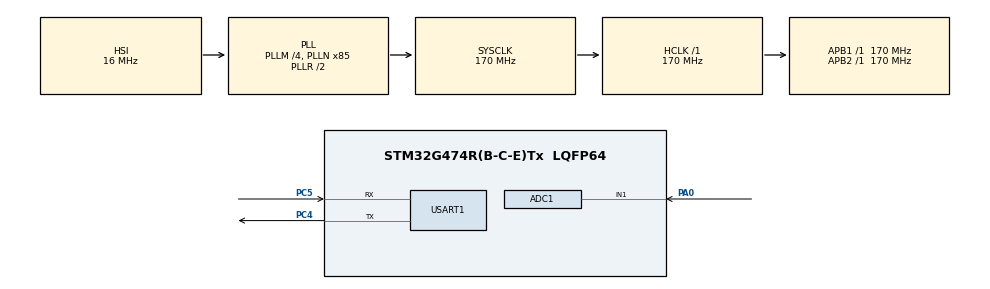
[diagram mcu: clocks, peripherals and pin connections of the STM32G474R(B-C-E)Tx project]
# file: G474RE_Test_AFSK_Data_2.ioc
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ADC1.Channel-0\#ChannelRegularConversion=ADC_CHANNEL_1
ADC1.ContinuousConvMode=ENABLE
ADC1.DMAContinuousRequests=ENABLE
ADC1.ExternalTrigConv=ADC_EXTERNALTRIG_T3_TRGO
ADC1.NbrOfConversionFlag=1
ADC1.OffsetNumber-0\#ChannelRegularConversion=ADC_OFFSET_NONE
ADC1.Rank-0\#ChannelRegularConversion=1
ADC1.SamplingTime-0\#ChannelRegularConversion=ADC_SAMPLETIME_640CYCLES_5
ADC1.master=1
Dma.ADC1.0.Direction=DMA_PERIPH_TO_MEMORY
Dma.ADC1.0.EventEnable=DISABLE
Dma.ADC1.0.Instance=DMA1_Channel1
Dma.ADC1.0.MemDataAlignment=DMA_MDATAALIGN_HALFWORD
Dma.ADC1.0.MemInc=DMA_MINC_ENABLE
Dma.ADC1.0.Mode=DMA_CIRCULAR
Dma.ADC1.0.PeriphDataAlignment=DMA_PDATAALIGN_HALFWORD
Dma.ADC1.0.PeriphInc=DMA_PINC_DISABLE
Dma.ADC1.0.Polarity=HAL_DMAMUX_REQ_GEN_RISING
Dma.ADC1.0.Priority=DMA_PRIORITY_MEDIUM
Dma.ADC1.0.RequestNumber=1
Dma.ADC1.0.SignalID=NONE
Dma.ADC1.0.SyncEnable=DISABLE
Dma.ADC1.0.SyncPolarity=HAL_DMAMUX_SYNC_NO_EVENT
Dma.ADC1.0.SyncRequestNumber=1
Dma.ADC1.0.SyncSignalID=NONE
Dma.Request0=ADC1
Mcu.Family=STM32G4
Mcu.Name=STM32G474R(B-C-E)Tx
Mcu.Package=LQFP64
NVIC.DMA1_Channel1_IRQn=true\:0\:0\:false\:false\:true\:false\:true\:true
NVIC.PriorityGroup=NVIC_PRIORITYGROUP_4
NVIC.TIM3_IRQn=true\:0\:0\:false\:false\:true\:true\:true\:true
PA0.Mode=IN1-Single-Ended
PA0.Signal=ADC1_IN1
PA13.Mode=Serial_Wire
PA13.Signal=SYS_JTMS-SWDIO
PA14.Mode=Serial_Wire
PA14.Signal=SYS_JTCK-SWCLK
PC14-OSC32_IN.Mode=LSE-External-Oscillator
PC14-OSC32_IN.Signal=RCC_OSC32_IN
PC15-OSC32_OUT.Mode=LSE-External-Oscillator
PC15-OSC32_OUT.Signal=RCC_OSC32_OUT
PC4.Mode=Asynchronous
PC4.Signal=USART1_TX
PC5.Mode=Asynchronous
PC5.Signal=USART1_RX
PF0-OSC_IN.Mode=HSE-External-Oscillator
PF0-OSC_IN.Signal=RCC_OSC_IN
PF1-OSC_OUT.Mode=HSE-External-Oscillator
PF1-OSC_OUT.Signal=RCC_OSC_OUT
ProjectManager.HeapSize=0x200
ProjectManager.StackSize=0x400
ProjectManager.TargetToolchain=STM32CubeIDE
RCC.ADC12Freq_Value=170000000
RCC.ADC345Freq_Value=170000000
RCC.AHBFreq_Value=170000000
RCC.APB1Freq_Value=170000000
RCC.APB1TimFreq_Value=170000000
RCC.APB2Freq_Value=170000000
RCC.APB2TimFreq_Value=170000000
RCC.CortexFreq_Value=170000000
RCC.EXTERNAL_CLOCK_VALUE=12288000
RCC.HCLKFreq_Value=170000000
RCC.HSE_VALUE=8000000
RCC.HSI48_VALUE=48000000
RCC.HSI_VALUE=16000000
RCC.PLLM=RCC_PLLM_DIV4
RCC.PLLN=85
RCC.SYSCLKFreq_VALUE=170000000
RCC.SYSCLKSource=RCC_SYSCLKSOURCE_PLLCLK
RCC.USBFreq_Value=170000000
RCC.VCOOutputFreq_Value=340000000
TIM3.PeriodNoDither=4249
TIM3.TIM_MasterOutputTrigger=TIM_TRGO_UPDATE
USART1.VirtualMode-Asynchronous=VM_ASYNC
VP_SYS_VS_DBSignals.Mode=DisableDeadBatterySignals
VP_TIM3_VS_ClockSourceINT.Mode=Internal
board=custom

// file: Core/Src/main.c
/* USER CODE BEGIN Header */
/**
 ******************************************************************************
 * @file           : main.c
 * @brief          : Main program body
 ******************************************************************************
 * @attention
 *
 * Copyright (c) 2025 STMicroelectronics.
 * All rights reserved.
 *
 * This software is licensed under terms that can be found in the LICENSE file
 * in the root directory of this software component.
 * If no LICENSE file comes with this software, it is provided AS-IS.
 *
 ******************************************************************************
 */
/* USER CODE END Header */
#include "main.h"

/* USER CODE BEGIN Includes */
#include <math.h>
#include <stdio.h>
#include <string.h>

/* USER CODE END Includes */

/* USER CODE BEGIN PTD */
#ifndef M_PI
#define M_PI 3.14159265358979323846f
#endif

#define SAMPLE_RATE     40000
#define BIT_RATE        100
#define SAMPLES_PER_BIT (SAMPLE_RATE/BIT_RATE)
#define FREQ_MARK       2500.0f
#define FREQ_SPACE      1500.0f
#define PREAMBLE_BYTE   0x55
#define PREAMBLE_COUNT  8
#define SYNC_BYTE       0xD5
#define MAX_PAYLOAD_LEN 64
/* USER CODE END PTD */

/* USER CODE BEGIN PD */
uint16_t adc_buf[SAMPLES_PER_BIT];
uint8_t bit_queue[16];
int q_idx = 0;
uint8_t frame[MAX_PAYLOAD_LEN];
uint8_t frame_len = 0;
uint8_t state = 0, preamble_seen = 0, len_expected = 0, crc_calc = 0;
/* USER CODE END PD */

ADC_HandleTypeDef hadc1;
DMA_HandleTypeDef hdma_adc1;

TIM_HandleTypeDef htim3;

UART_HandleTypeDef huart1;

void SystemClock_Config(void);
static void MX_GPIO_Init(void);
static void MX_DMA_Init(void);
static void MX_ADC1_Init(void);
static void MX_TIM3_Init(void);
static void MX_USART1_UART_Init(void);

/* USER CODE BEGIN 0 */
static uint8_t crc8(uint8_t crc, uint8_t data) {
	crc ^= data;
	for (int i = 0; i < 8; i++)
		crc = (crc & 0x80) ? ((crc << 1) ^ 0x07) : (crc << 1);
	return crc;
}

float goertzel(float freq, uint16_t *samples) {
	float omega = 2 * M_PI * freq / SAMPLE_RATE;
	float coeff = 2 * cosf(omega), s0 = 0, s1 = 0, s2 = 0;
	for (int i = 0; i < SAMPLES_PER_BIT; i++) {
		float x = (float) samples[i] - 2048;
		s0 = x + coeff * s1 - s2;
		s2 = s1;
		s1 = s0;
	}
	return s1 * s1 + s2 * s2 - coeff * s1 * s2;
}

void push_bit(uint8_t bit) {
	bit_queue[q_idx++] = bit;
	if (q_idx >= 10) {
		if (bit_queue[0] == 0 && bit_queue[9] == 1) {
			uint8_t val = 0;
			for (int i = 0; i < 8; i++)
				if (bit_queue[1 + i])
					val |= 1 << i;

			if (state == 0) {
				if (val == PREAMBLE_BYTE) {
					if (++preamble_seen >= PREAMBLE_COUNT)
						state = 1;
				} else
					preamble_seen = 0;
			} else if (state == 1) {
				if (val == SYNC_BYTE)
					state = 2;
				else if (val == PREAMBLE_BYTE) {
					state = 0;
					preamble_seen = 1;
				} else {
					state = 0;
					preamble_seen = 0;
				}
			} else if (state == 2) {
				len_expected = val;
				frame_len = 0;
				crc_calc = crc8(0, val);
				state = 3;
			} else if (state == 3) {
				frame[frame_len++] = val;
				crc_calc = crc8(crc_calc, val);
				if (frame_len >= len_expected)
					state = 4;
			} else if (state == 4) {
				if (val == crc_calc) {
					HAL_UART_Transmit(&huart1, (uint8_t*) "\r\n[RX] ", 7, 50);
					HAL_UART_Transmit(&huart1, frame, frame_len, 50);
				}
				state = 0;
				preamble_seen = 0;
			}
		}
		q_idx = 0;
	}
}

void HAL_ADC_ConvCpltCallback(ADC_HandleTypeDef *hadc) {
	float e_mark = goertzel(FREQ_MARK, adc_buf);
	float e_space = goertzel(FREQ_SPACE, adc_buf);
	push_bit(e_mark > e_space ? 1 : 0);
	HAL_ADC_Stop_DMA(&hadc1);
	HAL_ADC_Start_DMA(&hadc1, (uint32_t*) adc_buf, SAMPLES_PER_BIT);
}
/* USER CODE END 0 */

int main(void) {

	/* MCU Configuration--------------------------------------------------------*/

	/* Reset of all peripherals, Initializes the Flash interface and the Systick. */
	HAL_Init();

	/* Configure the system clock */
	SystemClock_Config();

	/* Initialize all configured peripherals */
	MX_GPIO_Init();
	MX_DMA_Init();
	MX_ADC1_Init();
	MX_TIM3_Init();
	MX_USART1_UART_Init();
	/* USER CODE BEGIN 2 */
	HAL_UART_Transmit(&huart1, (uint8_t*) "\r\nAFSK RX Ready\r\n", 16, 200);
	HAL_ADC_Start_DMA(&hadc1, (uint32_t*) adc_buf, SAMPLES_PER_BIT);

	/* USER CODE END 2 */

	/* Infinite loop */
	while (1) {

	}
}

void SystemClock_Config(void) {
	RCC_OscInitTypeDef RCC_OscInitStruct = { 0 };
	RCC_ClkInitTypeDef RCC_ClkInitStruct = { 0 };

	/** Configure the main internal regulator output voltage
	 */
	HAL_PWREx_ControlVoltageScaling(PWR_REGULATOR_VOLTAGE_SCALE1_BOOST);

	/** Initializes the RCC Oscillators according to the specified parameters
	 * in the RCC_OscInitTypeDef structure.
	 */
	RCC_OscInitStruct.OscillatorType = RCC_OSCILLATORTYPE_HSI;
	RCC_OscInitStruct.HSIState = RCC_HSI_ON;
	RCC_OscInitStruct.HSICalibrationValue = RCC_HSICALIBRATION_DEFAULT;
	RCC_OscInitStruct.PLL.PLLState = RCC_PLL_ON;
	RCC_OscInitStruct.PLL.PLLSource = RCC_PLLSOURCE_HSI;
	RCC_OscInitStruct.PLL.PLLM = RCC_PLLM_DIV4;
	RCC_OscInitStruct.PLL.PLLN = 85;
	RCC_OscInitStruct.PLL.PLLP = RCC_PLLP_DIV2;
	RCC_OscInitStruct.PLL.PLLQ = RCC_PLLQ_DIV2;
	RCC_OscInitStruct.PLL.PLLR = RCC_PLLR_DIV2;
	if (HAL_RCC_OscConfig(&RCC_OscInitStruct) != HAL_OK) {
		Error_Handler();
	}

	/** Initializes the CPU, AHB and APB buses clocks
	 */
	RCC_ClkInitStruct.ClockType = RCC_CLOCKTYPE_HCLK | RCC_CLOCKTYPE_SYSCLK
			| RCC_CLOCKTYPE_PCLK1 | RCC_CLOCKTYPE_PCLK2;
	RCC_ClkInitStruct.SYSCLKSource = RCC_SYSCLKSOURCE_PLLCLK;
	RCC_ClkInitStruct.AHBCLKDivider = RCC_SYSCLK_DIV1;
	RCC_ClkInitStruct.APB1CLKDivider = RCC_HCLK_DIV1;
	RCC_ClkInitStruct.APB2CLKDivider = RCC_HCLK_DIV1;

	if (HAL_RCC_ClockConfig(&RCC_ClkInitStruct, FLASH_LATENCY_4) != HAL_OK) {
		Error_Handler();
	}
}

static void MX_ADC1_Init(void) {

	ADC_MultiModeTypeDef multimode = { 0 };
	ADC_ChannelConfTypeDef sConfig = { 0 };

	/** Common config
	 */
	hadc1.Instance = ADC1;
	hadc1.Init.ClockPrescaler = ADC_CLOCK_SYNC_PCLK_DIV4;
	hadc1.Init.Resolution = ADC_RESOLUTION_12B;
	hadc1.Init.DataAlign = ADC_DATAALIGN_RIGHT;
	hadc1.Init.GainCompensation = 0;
	hadc1.Init.ScanConvMode = ADC_SCAN_DISABLE;
	hadc1.Init.EOCSelection = ADC_EOC_SINGLE_CONV;
	hadc1.Init.LowPowerAutoWait = DISABLE;
	hadc1.Init.ContinuousConvMode = ENABLE;
	hadc1.Init.NbrOfConversion = 1;
	hadc1.Init.DiscontinuousConvMode = DISABLE;
	hadc1.Init.ExternalTrigConv = ADC_EXTERNALTRIG_T3_TRGO;
	hadc1.Init.ExternalTrigConvEdge = ADC_EXTERNALTRIGCONVEDGE_RISING;
	hadc1.Init.DMAContinuousRequests = ENABLE;
	hadc1.Init.Overrun = ADC_OVR_DATA_PRESERVED;
	hadc1.Init.OversamplingMode = DISABLE;
	if (HAL_ADC_Init(&hadc1) != HAL_OK) {
		Error_Handler();
	}

	/** Configure the ADC multi-mode
	 */
	multimode.Mode = ADC_MODE_INDEPENDENT;
	if (HAL_ADCEx_MultiModeConfigChannel(&hadc1, &multimode) != HAL_OK) {
		Error_Handler();
	}

	/** Configure Regular Channel
	 */
	sConfig.Channel = ADC_CHANNEL_1;
	sConfig.Rank = ADC_REGULAR_RANK_1;
	sConfig.SamplingTime = ADC_SAMPLETIME_640CYCLES_5;
	sConfig.SingleDiff = ADC_SINGLE_ENDED;
	sConfig.OffsetNumber = ADC_OFFSET_NONE;
	sConfig.Offset = 0;
	if (HAL_ADC_ConfigChannel(&hadc1, &sConfig) != HAL_OK) {
		Error_Handler();
	}

}

static void MX_TIM3_Init(void) {

	TIM_ClockConfigTypeDef sClockSourceConfig = { 0 };
	TIM_MasterConfigTypeDef sMasterConfig = { 0 };

	htim3.Instance = TIM3;
	htim3.Init.Prescaler = 0;
	htim3.Init.CounterMode = TIM_COUNTERMODE_UP;
	htim3.Init.Period = 4249;
	htim3.Init.ClockDivision = TIM_CLOCKDIVISION_DIV1;
	htim3.Init.AutoReloadPreload = TIM_AUTORELOAD_PRELOAD_DISABLE;
	if (HAL_TIM_Base_Init(&htim3) != HAL_OK) {
		Error_Handler();
	}
	sClockSourceConfig.ClockSource = TIM_CLOCKSOURCE_INTERNAL;
	if (HAL_TIM_ConfigClockSource(&htim3, &sClockSourceConfig) != HAL_OK) {
		Error_Handler();
	}
	sMasterConfig.MasterOutputTrigger = TIM_TRGO_UPDATE;
	sMasterConfig.MasterSlaveMode = TIM_MASTERSLAVEMODE_DISABLE;
	if (HAL_TIMEx_MasterConfigSynchronization(&htim3, &sMasterConfig)
			!= HAL_OK) {
		Error_Handler();
	}

}

static void MX_USART1_UART_Init(void) {

	huart1.Instance = USART1;
	huart1.Init.BaudRate = 115200;
	huart1.Init.WordLength = UART_WORDLENGTH_8B;
	huart1.Init.StopBits = UART_STOPBITS_1;
	huart1.Init.Parity = UART_PARITY_NONE;
	huart1.Init.Mode = UART_MODE_TX_RX;
	huart1.Init.HwFlowCtl = UART_HWCONTROL_NONE;
	huart1.Init.OverSampling = UART_OVERSAMPLING_16;
	huart1.Init.OneBitSampling = UART_ONE_BIT_SAMPLE_DISABLE;
	huart1.Init.ClockPrescaler = UART_PRESCALER_DIV1;
	huart1.AdvancedInit.AdvFeatureInit = UART_ADVFEATURE_NO_INIT;
	if (HAL_UART_Init(&huart1) != HAL_OK) {
		Error_Handler();
	}
	if (HAL_UARTEx_SetTxFifoThreshold(&huart1, UART_TXFIFO_THRESHOLD_1_8)
			!= HAL_OK) {
		Error_Handler();
	}
	if (HAL_UARTEx_SetRxFifoThreshold(&huart1, UART_RXFIFO_THRESHOLD_1_8)
			!= HAL_OK) {
		Error_Handler();
	}
	if (HAL_UARTEx_DisableFifoMode(&huart1) != HAL_OK) {
		Error_Handler();
	}

}

static void MX_DMA_Init(void) {

	/* DMA controller clock enable */
	__HAL_RCC_DMAMUX1_CLK_ENABLE();
	__HAL_RCC_DMA1_CLK_ENABLE();

	/* DMA interrupt init */
	/* DMA1_Channel1_IRQn interrupt configuration */
	HAL_NVIC_SetPriority(DMA1_Channel1_IRQn, 0, 0);
	HAL_NVIC_EnableIRQ(DMA1_Channel1_IRQn);

}

static void MX_GPIO_Init(void) {

	/* GPIO Ports Clock Enable */
	__HAL_RCC_GPIOC_CLK_ENABLE();
	__HAL_RCC_GPIOF_CLK_ENABLE();
	__HAL_RCC_GPIOA_CLK_ENABLE();

}

void Error_Handler(void) {
	__disable_irq();
	while (1) {
	}
}
